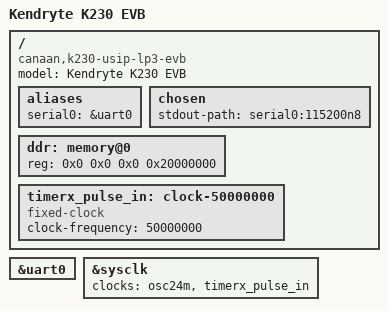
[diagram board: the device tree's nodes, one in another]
// SPDX-License-Identifier: GPL-2.0 OR MIT
/*
 * Copyright (C) 2024 Yangyu Chen <cyy@cyyself.name>
 */

#include "k230.dtsi"

/ {
	model = "Kendryte K230 EVB";
	compatible = "canaan,k230-usip-lp3-evb", "canaan,kendryte-k230";

	aliases {
		serial0 = &uart0;
	};

	chosen {
		stdout-path = "serial0:115200n8";
	};

	ddr: memory@0 {
		device_type = "memory";
		reg = <0x0 0x0 0x0 0x20000000>;
	};

	timerx_pulse_in: clock-50000000 {
		compatible = "fixed-clock";
		#clock-cells = <0>;
		clock-frequency = <50000000>;
	};
};

&uart0 {
	status = "okay";
};

&sysclk {
	clocks = <&osc24m>, <&timerx_pulse_in>;
	clock-names = "osc24m", "timer-pulse-in";
};
